AUTOSAR XML (schema 00048)
package /AUTOLIV/SoftwareComponents/MMG
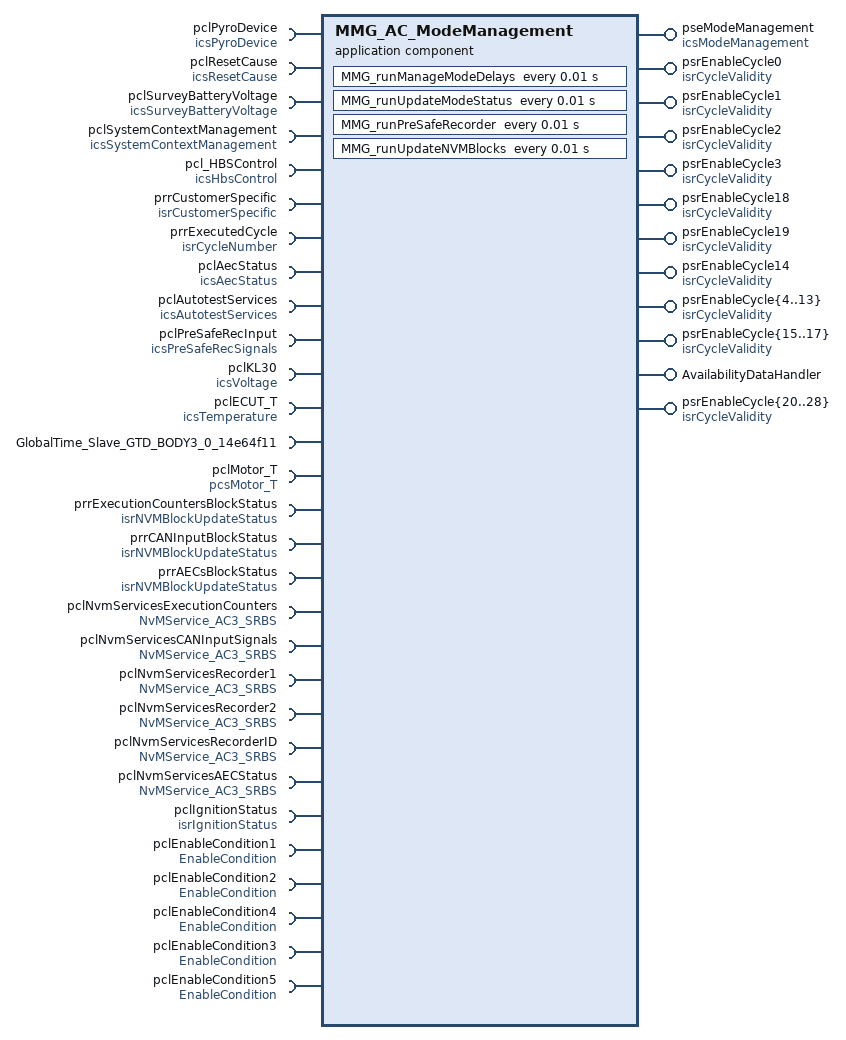
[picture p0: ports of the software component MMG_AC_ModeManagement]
  application sw component type MMG_AC_ModeManagement
    7 x require port:
      pclPyroDevice: client-com-spec=GetPyroActivationStatus, required-interface=icsPyroDevice
      pclResetCause: required-com-specs=[ConfirmResetCause, DetermineResetCause, GetResetCause], required-interface=icsResetCause  # Port to get reset cause
      pclSurveyBatteryVoltage: required-com-specs=[GetStatus, Monitor], required-interface=icsSurveyBatteryVoltage
      pclSystemContextManagement: required-interface=icsSystemContextManagement
        required-com-specs:
          GetBatteryHysteresisThrs
          GetLastTensionningState
          GetMonitoredCycle
          ManageSystemContextStorage
          RestoreSystemContext
          SuperviseKL30bg
      pcl_HBSControl: required-com-specs=[DisableHBSMonitoring, EnableHBSMonitoring], required-interface=icsHbsControl
      prrCustomerSpecific: required-interface=isrCustomerSpecific
        required-com-specs:
          data-element=b8HardReleaseRequest
          data-element=b8IsCarCrankingActive, init-value=constant-reference=APPLINIT_KB8_CAR_CRANKING_ACTIVE_TRUE
          data-element=b8IsCarCrashDetected, init-value=constant-reference=APPLINIT_KB8_CAR_CRASH_DETECTED_FALSE
          data-element=b8IsTrigOffEventAllowed
          data-element=b8PreCrashRequestEnable, init-value=constant-reference=APPLINIT_KB8_BOOLEAN_FALSE
          data-element=u8BeltSlackStatus, init-value=constant-reference=APPLINIT_KU8_BELT_SLACK_STATUS_NOT_DEFINED
          data-element=u8HapticRequest, init-value=constant-reference=APPLINIT_KU8_HAPTIC_REQUEST_NO
          data-element=u8PreCrashRequest, init-value=constant-reference=APPLINIT_KU8_PRE_CRASH_REQUEST_NO_REQUEST
          data-element=u8TriggerRequest
          data-element=b8SignalRelInhibition
      prrExecutedCycle: nonqueued-receiver-com-spec{data-element=u8CycleNumber, init-value=constant-reference=APPLINIT_KU8_CYCLE_NUMBER_NONE}, required-interface=isrCycleNumber
    provide port pseModeManagement: server-com-spec{operation=CheckModeStatus, queue-length=1}, provided-interface=icsModeManagement
    provide port psrEnableCycle0: nonqueued-sender-com-spec=b8CycleValidity, provided-interface=isrCycleValidity
    provide port psrEnableCycle1: nonqueued-sender-com-spec=b8CycleValidity, provided-interface=isrCycleValidity
    require port pclAecStatus: required-interface=icsAecStatus
      required-com-specs:
        SetAecEvent
        GetNumberOfImplementedAec
        GetAecStatus
        GetAecQualificationCount
        GetAecNvpBlockRecordingStatus
        GetAecGroupsStatus
        GetAecDeskillThrs
    require port pclAutotestServices: required-com-specs=[GetLastCriticalAutotestID, GetTestResult], required-interface=icsAutotestServices
    5 x provide port, all with nonqueued-sender-com-spec=b8CycleValidity, provided-interface=isrCycleValidity:
      psrEnableCycle2
      psrEnableCycle3
      psrEnableCycle18
      psrEnableCycle19
      psrEnableCycle14
    4 x require port:
      pclPreSafeRecInput: client-com-spec=GetInputSignals, required-interface=icsPreSafeRecSignals
      pclKL30: required-com-specs=[Get_2ms, Get_20ms, Get_10ms, Get_100ms, Get], required-interface=icsVoltage
      pclECUT_T: required-com-specs=[Init, GetFiltered_deg, GetFiltered], required-interface=icsTemperature
      GlobalTime_Slave_GTD_BODY3_0_14e64f11: required-com-specs=[GetSyncTimeRecordHead, GetTimeBaseStatus, GetTimeLeap, GetRateDeviation, GetCurrentTime], required-interface=GlobalTime_Slave_GTD_BODY3_0_14e64f11
    13 x provide port, all with nonqueued-sender-com-spec=b8CycleValidity, provided-interface=isrCycleValidity:
      psrEnableCycle{4..13}
      psrEnableCycle{15..17}
    require port pclMotor_T: required-com-specs=[InitializeDeficiencyLevel, GetDeficiencyLevel], required-interface=pcsMotor_T
    10 x provide port:
      AvailabilityDataHandler: nonqueued-sender-com-spec{data-element=AvailabilityDataCategory, init-value=0}, provided-interface=AvailabilityDataHandler
      psrEnableCycle{20..28}: nonqueued-sender-com-spec=b8CycleValidity, provided-interface=isrCycleValidity
    15 x require port:
      prrExecutionCountersBlockStatus: nonqueued-receiver-com-spec{data-element=b8NVMBlockStatus, enable-update=true, filter=data-filter-type=ALWAYS, init-value=constant-reference=IMPLINIT_KB8_BOOLEAN_FALSE}, required-interface=isrNVMBlockUpdateStatus
      prrCANInputBlockStatus: nonqueued-receiver-com-spec{data-element=b8NVMBlockStatus, enable-update=true, filter=data-filter-type=ALWAYS, init-value=constant-reference=IMPLINIT_KB8_BOOLEAN_FALSE}, required-interface=isrNVMBlockUpdateStatus
      prrAECsBlockStatus: nonqueued-receiver-com-spec{data-element=b8NVMBlockStatus, enable-update=true, filter=data-filter-type=ALWAYS, init-value=constant-reference=IMPLINIT_KB8_BOOLEAN_FALSE}, required-interface=isrNVMBlockUpdateStatus
      pclNvmServicesExecutionCounters: required-com-specs=[EraseBlock, InvalidateNvBlock, WriteBlock, ReadBlock, SetRamBlockStatus, GetErrorStatus], required-interface=NvMService_AC3_SRBS
      pclNvmServicesCANInputSignals: required-com-specs=[EraseBlock, InvalidateNvBlock, WriteBlock, ReadBlock, SetRamBlockStatus, GetErrorStatus], required-interface=NvMService_AC3_SRBS
      pclNvmServicesRecorder1: required-com-specs=[EraseBlock, InvalidateNvBlock, WriteBlock, ReadBlock, SetRamBlockStatus, GetErrorStatus], required-interface=NvMService_AC3_SRBS
      pclNvmServicesRecorder2: required-com-specs=[EraseBlock, InvalidateNvBlock, WriteBlock, ReadBlock, SetRamBlockStatus, GetErrorStatus], required-interface=NvMService_AC3_SRBS
      pclNvmServicesRecorderID: required-com-specs=[EraseBlock, InvalidateNvBlock, WriteBlock, ReadBlock, SetRamBlockStatus, GetErrorStatus], required-interface=NvMService_AC3_SRBS
      pclNvmServicesAECStatus: required-com-specs=[EraseBlock, InvalidateNvBlock, WriteBlock, ReadBlock, SetRamBlockStatus, GetErrorStatus], required-interface=NvMService_AC3_SRBS
      pclIgnitionStatus: required-interface=isrIgnitionStatus
        required-com-specs:
          data-element=b8TriggerIgnitionStatus, filter=data-filter-type=ALWAYS, init-value=constant-reference=APPLINIT_KB8_BOOLEAN_FALSE
          data-element=b8TriggerIgnitionStatusEnableStorageCondition, filter=data-filter-type=ALWAYS, init-value=constant-reference=APPLINIT_KB8_BOOLEAN_FALSE
      pclEnableCondition1: client-com-spec=SetEnableCondition, required-interface=EnableCondition
      pclEnableCondition2: client-com-spec=SetEnableCondition, required-interface=EnableCondition
      pclEnableCondition4: client-com-spec=SetEnableCondition, required-interface=EnableCondition
      pclEnableCondition3: client-com-spec=SetEnableCondition, required-interface=EnableCondition
      pclEnableCondition5: client-com-spec=SetEnableCondition, required-interface=EnableCondition
    behavior MMG_IB_ModeManagement: data-type-mapping=DataTypeMappingSet_PP4G
      operation invoked event MMG_evCheckSystemContext: start-on-event=MMG_runCheckModeStatus, operation=pseModeManagement.CheckModeStatus
      timing event MMG_evManageModeDelays: start-on-event=MMG_runManageModeDelays, period=0.01
      timing event MMG_evUpdateModeStatus: start-on-event=MMG_runUpdateModeStatus, period=0.01
      init event MMG_InitEvent: start-on-event=MMG_Init
      timing event TMT_MMG_runPreSafeRecorder: start-on-event=MMG_runPreSafeRecorder, period=0.01
      timing event MMG_evUpdateNVMBlocks: start-on-event=MMG_runUpdateNVMBlocks, period=0.01
      explicit-inter-runnable-variables:
        data b8PreSafeRecorder1Update: type=UInt8, init-value=constant-reference=IMPLINIT_KB8_BOOLEAN_FALSE
        data b8PreSafeRecorder2Update: type=UInt8, init-value=constant-reference=IMPLINIT_KB8_BOOLEAN_FALSE
      6 x runnable:
        MMG_Init
          data-send-points:
            29 x access:
              SEND_psrEnableCycle0_Element: accessed-variable=psrEnableCycle0.b8CycleValidity
              SEND_psrEnableCycle1_Element: accessed-variable=psrEnableCycle1.b8CycleValidity
              SEND_psrEnableCycle2_b8CycleValidity: accessed-variable=psrEnableCycle2.b8CycleValidity
              SEND_psrEnableCycle3_b8CycleValidity: accessed-variable=psrEnableCycle3.b8CycleValidity
              SEND_psrEnableCycle14_b8CycleValidity: accessed-variable=psrEnableCycle14.b8CycleValidity
              SEND_psrEnableCycle18_b8CycleValidity: accessed-variable=psrEnableCycle18.b8CycleValidity
              SEND_psrEnableCycle19_b8CycleValidity: accessed-variable=psrEnableCycle19.b8CycleValidity
              SEND_psrEnableCycle{10..13}_b8CycleValidity: accessed-variable=psrEnableCycle{10..13}.b8CycleValidity
              SEND_psrEnableCycle{15..17}_b8CycleValidity: accessed-variable=psrEnableCycle{15..17}.b8CycleValidity
              SEND_psrEnableCycle{4..9}_b8CycleValidity: accessed-variable=psrEnableCycle{4..9}.b8CycleValidity
              SEND_psrEnableCycle{20..28}_b8CycleValidity: accessed-variable=psrEnableCycle{20..28}.b8CycleValidity
          8 x sync call:
            SC_pclAecStatus_GetAecGroupsStatus: operation=pclAecStatus.GetAecGroupsStatus
            SC_pclAecStatus_GetAecStatus: operation=pclAecStatus.GetAecStatus
            SC_pclAecStatus_GetNumberOfImplementedAec: operation=pclAecStatus.GetNumberOfImplementedAec
            SC_pclAutotestServices_GetLastCriticalAutotestID: operation=pclAutotestServices.GetLastCriticalAutotestID
            SC_pclAutotestServices_GetTestResult: operation=pclAutotestServices.GetTestResult
            SC_pclSurveyBatteryVoltage_GetStatus: operation=pclSurveyBatteryVoltage.GetStatus
            SC_pcl_HBSControl_DisableHBSMonitoring: operation=pcl_HBSControl.DisableHBSMonitoring
            SC_pcl_HBSControl_EnableHBSMonitoring: operation=pcl_HBSControl.EnableHBSMonitoring
        MMG_runCheckModeStatus: can-be-invoked-concurrently=true
          data-receive-point-by-arguments:
            access REC_pclIgnitionStatus_b8TriggerIgnitionStatusEnableCondition: accessed-variable=pclIgnitionStatus.b8TriggerIgnitionStatusEnableStorageCondition
          5 x sync call:
            SC_pclEnableCondition{1..5}_SetEnableCondition: operation=pclEnableCondition{1..5}.SetEnableCondition
        MMG_runManageModeDelays: can-be-invoked-concurrently=true
          sync call SSCP_pclPyroDevice_GetPyroActivationStatus: operation=pclPyroDevice.GetPyroActivationStatus
          sync call SSCP_pclResetCause_GetResetCause: operation=pclResetCause.GetResetCause
          sync call scp_GetLastTensionningState: operation=pclSystemContextManagement.GetLastTensionningState
        MMG_runUpdateModeStatus: can-be-invoked-concurrently=true
          data-receive-point-by-arguments:
            access DRP_prrCustomerSpecific_b8IsCarCrankingActive: accessed-variable=prrCustomerSpecific.b8IsCarCrankingActive
            access DRP_prrExecutedCycle_u8CycleNumber: accessed-variable=prrExecutedCycle.u8CycleNumber
            access REC_prrCustomerSpecific_b8SignalRelInhibition: accessed-variable=prrCustomerSpecific.b8SignalRelInhibition
          data-send-points:
            access SEND_AvailabilityDataHandler_AvailabilityDataCategory: accessed-variable=AvailabilityDataHandler.AvailabilityDataCategory
          6 x sync call:
            SSCP_pclPyroDevice_GetPyroActivationStatus: operation=pclPyroDevice.GetPyroActivationStatus
            SSCP_pclSurveyBatteryVoltage_GetStatus: operation=pclSurveyBatteryVoltage.GetStatus
            scp_DisableHBSMonitoring: operation=pcl_HBSControl.DisableHBSMonitoring
            scp_EnableHBSMonitoring: operation=pcl_HBSControl.EnableHBSMonitoring
            SC_pclResetCause_GetResetCause: operation=pclResetCause.GetResetCause
            SC_pclEnableCondition_SetEnableCondition: operation=pclEnableCondition1.SetEnableCondition
        MMG_runPreSafeRecorder
          5 x sync call:
            SC_pclPreSafeRecInput_GetInputSignals: operation=pclPreSafeRecInput.GetInputSignals
            SC_pclKL30_Get: operation=pclKL30.Get
            SC_pclECUT_T_GetFiltered_deg: operation=pclECUT_T.GetFiltered_deg
            SC_GlobalTime_Slave_GTD_BODY3_0_14e64f11_GetCurrentTime: operation=GlobalTime_Slave_GTD_BODY3_0_14e64f11.GetCurrentTime
            SC_pclMotor_T_GetDeficiencyLevel: operation=pclMotor_T.GetDeficiencyLevel
          written-local-variables:
            access WRITE_b8PreSaf: accessed-variable=b8PreSafeRecorder1Update
            access WRITE_b8PreSafeRecorder2Update: accessed-variable=b8PreSafeRecorder2Update
        MMG_runUpdateNVMBlocks
          data-receive-point-by-arguments:
            access REC_prrExecutionCountersBlockStatus_b8NVMBlockStatus: accessed-variable=prrExecutionCountersBlockStatus.b8NVMBlockStatus
            access REC_prrCANInputBlockStatus_b8NVMBlockStatus: accessed-variable=prrCANInputBlockStatus.b8NVMBlockStatus
            access REC_prrAECsBlockStatus_b8NVMBlockStatus: accessed-variable=prrAECsBlockStatus.b8NVMBlockStatus
          read-local-variables:
            access Read_b8PreSaf: accessed-variable=b8PreSafeRecorder1Update
            access Read_b8PreSafeRecorder2Update: accessed-variable=b8PreSafeRecorder2Update
          12 x sync call:
            SC_pclNvmServicesExecutionCounters_GetErrorStatus: operation=pclNvmServicesExecutionCounters.GetErrorStatus
            SC_pclNvmServicesExecutionCounters_WriteBlock: operation=pclNvmServicesExecutionCounters.WriteBlock
            SC_pclNvmServicesAECStatus_GetErrorStatus: operation=pclNvmServicesAECStatus.GetErrorStatus
            SC_pclNvmServicesAECStatus_WriteBlock: operation=pclNvmServicesAECStatus.WriteBlock
            SC_pclNvmServicesCANInputSignals_GetErrorStatus: operation=pclNvmServicesCANInputSignals.GetErrorStatus
            SC_pclNvmServicesCANInputSignals_WriteBlock: operation=pclNvmServicesCANInputSignals.WriteBlock
            SC_pclNvmServicesRecorder1_GetErrorStatus: operation=pclNvmServicesRecorder1.GetErrorStatus
            SC_pclNvmServicesRecorder1_WriteBlock: operation=pclNvmServicesRecorder1.WriteBlock
            SC_pclNvmServicesRecorder2_GetErrorStatus: operation=pclNvmServicesRecorder2.GetErrorStatus
            SC_pclNvmServicesRecorder2_WriteBlock: operation=pclNvmServicesRecorder2.WriteBlock
            SC_pclNvmServicesRecorderID_GetErrorStatus: operation=pclNvmServicesRecorderID.GetErrorStatus
            SC_pclNvmServicesRecorderID_WriteBlock: operation=pclNvmServicesRecorderID.WriteBlock
  swc implementation MMG_AC_ModeManagement_Implementation: behavior=MMG_IB_ModeManagement
